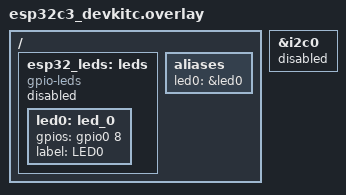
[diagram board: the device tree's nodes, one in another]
/*
 * Copyright (c) 2026
 * SPDX-License-Identifier: Apache-2.0
 *
 * ESP32-C3 DevKitC. Unlike the other machines here, nothing on this board is a
 * browser-backed *device*: the peripherals are the SoC's own, modelled in
 * QEMU, and the guest drives them with the stock Zephyr esp32 drivers. What
 * the browser supplies is what would be wired to them.
 *
 * GPIO: the page watches the pins through the same two exported functions the
 * Cortex-M3's qemu,host-gpio device provides, so src/hostGpio.ts binds to
 * either. I2C: hw/i2c/host_i2c.c sits on the controller's bus and answers for
 * whichever chips the page has attached, so src/hostI2c.ts puts the same
 * models on it that the Cortex-A53 reaches over VIRTIO.
 *
 * The board devicetree already brings a button: `sw0` is a gpio-keys node on
 * GPIO9, active low with a pull-up, so the button sample needs no overlay at
 * all. It has no LED, though, so blinky needs the node below.
 *
 * GPIO8 is where the DevKitM-1 puts its addressable RGB LED. A plain gpio-leds
 * node is the browser stand-in for it: the panel shows a pin going high, which
 * is what blinky is demonstrating.
 *
 * As on the other boards, the node is declared `status = "disabled"` and a
 * snippet turns it on: `-S esp32-leds`. The shield says where the device is;
 * the manifest says which images carry it, because the dock is grounded in the
 * running build's devicetree.
 */

#include <zephyr/dt-bindings/gpio/gpio.h>

/ {
	esp32_leds: leds {
		compatible = "gpio-leds";
		status = "disabled";

		led0: led_0 {
			gpios = <&gpio0 8 GPIO_ACTIVE_HIGH>;
			label = "LED0";
		};
	};

	aliases {
		led0 = &led0;
	};
};

/*
 * The board devicetree turns i2c0 on unconditionally, because a real DevKitC
 * really does have that controller with those pins. Here it is off unless a
 * sample asks for it with `-S esp32-i2c`, which is also where the parts bin
 * lives: the device dock is grounded in the running build's flattened
 * devicetree, so a bus left on for hello_world is a card the user has to look
 * past. Same rule as the LED node above.
 */
&i2c0 {
	status = "disabled";
};
